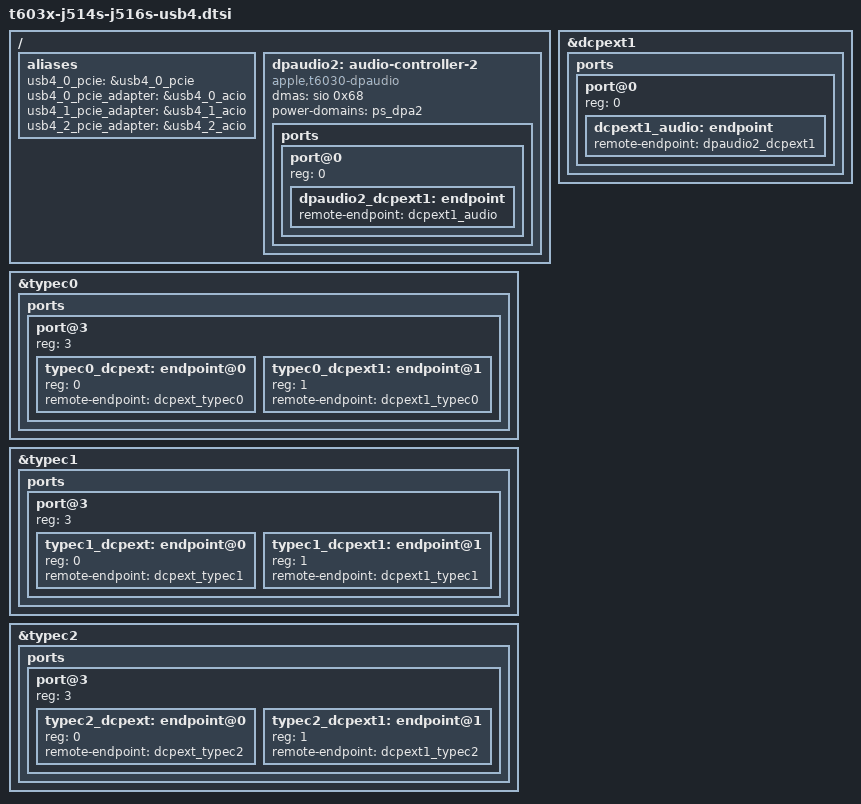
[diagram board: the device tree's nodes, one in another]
// SPDX-License-Identifier: GPL-2.0+ OR MIT
/*
 * J514S/J516S: loader aliases for the T6030 PCIe adapter tunables, and the
 * Type-C display routes of both external processors with dcpext1's audio.
 */

/ {
	aliases {
		usb4_0_pcie = &usb4_0_pcie;
		usb4_0_pcie_adapter = &usb4_0_acio;
		usb4_1_pcie_adapter = &usb4_1_acio;
		usb4_2_pcie_adapter = &usb4_2_acio;
	};
};

&typec0 {
	ports {
		port@3 {
			reg = <3>;
			#address-cells = <1>;
			#size-cells = <0>;

			typec0_dcpext: endpoint@0 {
				reg = <0>;
				remote-endpoint = <&dcpext_typec0>;
			};

			typec0_dcpext1: endpoint@1 {
				reg = <1>;
				remote-endpoint = <&dcpext1_typec0>;
			};
		};
	};
};

&typec1 {
	ports {
		port@3 {
			reg = <3>;
			#address-cells = <1>;
			#size-cells = <0>;

			typec1_dcpext: endpoint@0 {
				reg = <0>;
				remote-endpoint = <&dcpext_typec1>;
			};

			typec1_dcpext1: endpoint@1 {
				reg = <1>;
				remote-endpoint = <&dcpext1_typec1>;
			};
		};
	};
};

&typec2 {
	ports {
		port@3 {
			reg = <3>;
			#address-cells = <1>;
			#size-cells = <0>;

			typec2_dcpext: endpoint@0 {
				reg = <0>;
				remote-endpoint = <&dcpext_typec2>;
			};

			typec2_dcpext1: endpoint@1 {
				reg = <1>;
				remote-endpoint = <&dcpext1_typec2>;
			};
		};
	};
};

/* DPA2: dcpext1's audio on SIO channel 0x68, as the ADT links them. */
&dcpext1 {
	ports {
		#address-cells = <1>;
		#size-cells = <0>;

		port@0 {
			reg = <0>;
			dcpext1_audio: endpoint {
				remote-endpoint = <&dpaudio2_dcpext1>;
			};
		};
	};
};

/* DPA2, like DPA1, has no AP-side registers: not a child of the SoC bus. */
/ {
	dpaudio2: audio-controller-2 {
		compatible = "apple,t6030-dpaudio", "apple,dpaudio";
		dmas = <&sio 0x68>;
		dma-names = "tx";
		power-domains = <&ps_dpa2>;

		ports {
			#address-cells = <1>;
			#size-cells = <0>;

			port@0 {
				reg = <0>;
				dpaudio2_dcpext1: endpoint {
					remote-endpoint = <&dcpext1_audio>;
				};
			};
		};
	};
};
